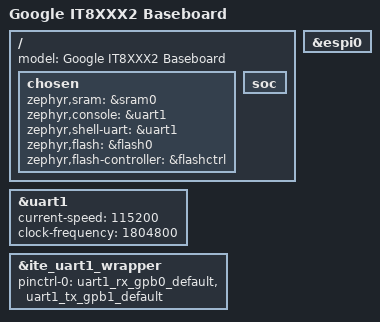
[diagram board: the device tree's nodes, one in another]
/* Copyright 2021 The ChromiumOS Authors
 * Use of this source code is governed by a BSD-style license that can be
 * found in the LICENSE file.
 */

#include <cros/ite/it8xxx2.dtsi>
#include <dt-bindings/gpio_defines.h>
#include <dt-bindings/gpio/ite-it8xxx2-gpio.h>
#include <ite/it8xxx2-pinctrl-map.dtsi>

#define GPIO_VOLTAGE_1P8 IT8XXX2_GPIO_VOLTAGE_1P8

/ {
	model = "Google IT8XXX2 Baseboard";

	chosen {
		zephyr,sram = &sram0;
		zephyr,console = &uart1;
		zephyr,shell-uart = &uart1;
		zephyr,flash = &flash0;
		zephyr,flash-controller = &flashctrl;
	};

	/* Override keyboard scanning */
	soc {
		/delete-node/ kbd@f01d00;
	};
};

&uart1 {
	status = "okay";
	current-speed = <115200>;
	clock-frequency = <1804800>;
};

&ite_uart1_wrapper {
	status = "okay";
	pinctrl-0 = <&uart1_rx_gpb0_default
		     &uart1_tx_gpb1_default>;
	pinctrl-names = "default";
};

&espi0 {
	status = "okay";
};
